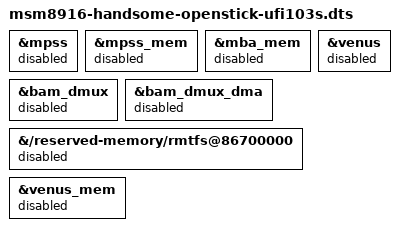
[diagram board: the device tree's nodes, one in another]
// SPDX-License-Identifier: GPL-2.0-only
/*
 * Handsome OpenStick UFI103s - WiFi-only 板型
 *
 * 功能集：Wi-Fi/BT（WCNSS）+ USB 网络共享 + OC（全员，见 common dtsi）。
 * 无 4G、无硬件编解码、无 GPU——按命名规范（"无此功能则不写"），后缀为空。
 *
 * 在 4G 板型（…-4g.dts）的基础上关闭整条 modem/PIL 链，被 no-map 预留的
 * 内存直接回到系统（实测 +86.7MB）：mpss 85M + mba 1M + rmtfs 0.9M。
 * venus/venus_mem 显式关闭（防 venus_mem 的 5MB 默认预留）。
 */

#include "msm8916-handsome-openstick-ufi103s-4g.dts"

&mpss {
	status = "disabled";
};

&mpss_mem {
	status = "disabled";
};

&mba_mem {
	status = "disabled";
};

&bam_dmux {
	status = "disabled";
};

&bam_dmux_dma {
	status = "disabled";
};

/* 无 label，按路径禁用（qcom,rmtfs-mem） */
&{/reserved-memory/rmtfs@86700000} {
	status = "disabled";
};

&venus {
	status = "disabled";
};

&venus_mem {
	status = "disabled";
};
